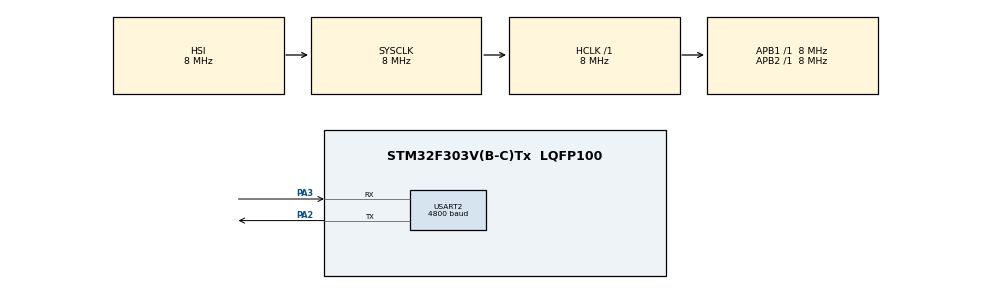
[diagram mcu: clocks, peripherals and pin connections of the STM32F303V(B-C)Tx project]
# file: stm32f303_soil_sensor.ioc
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Mcu.Family=STM32F3
Mcu.Name=STM32F303V(B-C)Tx
Mcu.Package=LQFP100
NVIC.PriorityGroup=NVIC_PRIORITYGROUP_4
NVIC.USART2_IRQn=true\:0\:0\:false\:false\:true\:true\:true\:true
PA13.Mode=Serial_Wire
PA13.Signal=SYS_JTMS-SWDIO
PA14.Mode=Serial_Wire
PA14.Signal=SYS_JTCK-SWCLK
PA2.Mode=Asynchronous
PA2.Signal=USART2_TX
PA3.Mode=Asynchronous
PA3.Signal=USART2_RX
PF0-OSC_IN.Mode=HSE-External-Oscillator
PF0-OSC_IN.Signal=RCC_OSC_IN
PF1-OSC_OUT.Mode=HSE-External-Oscillator
PF1-OSC_OUT.Signal=RCC_OSC_OUT
ProjectManager.HeapSize=0x200
ProjectManager.StackSize=0x400
ProjectManager.TargetToolchain=STM32CubeIDE
RCC.AHBFreq_Value=8000000
RCC.APB1Freq_Value=8000000
RCC.APB2Freq_Value=8000000
RCC.CortexFreq_Value=8000000
RCC.HSE_VALUE=8000000
RCC.HSI_VALUE=8000000
RCC.LSE_VALUE=32768
RCC.SYSCLKFreq_VALUE=8000000
USART2.BaudRate=4800
USART2.VirtualMode-Asynchronous=VM_ASYNC
board=custom

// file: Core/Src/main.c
/* USER CODE BEGIN Header */
/**
  ******************************************************************************
  * @file           : main.c
  * @brief          : Main program body
  ******************************************************************************
  * @attention
  *
  * Copyright (c) 2025 STMicroelectronics.
  * All rights reserved.
  *
  * This software is licensed under terms that can be found in the LICENSE file
  * in the root directory of this software component.
  * If no LICENSE file comes with this software, it is provided AS-IS.
  *
  ******************************************************************************
  */
/* USER CODE END Header */
#include "main.h"

/* USER CODE BEGIN Includes */
#include "modbus_crc.h"
#include "stdint.h"
/* USER CODE END Includes */

UART_HandleTypeDef huart2;

/* USER CODE BEGIN PV */
uint8_t uart2_tx_data[8];
/* USER CODE END PV */

void SystemClock_Config(void);
static void MX_GPIO_Init(void);
static void MX_USART2_UART_Init(void);
/* USER CODE BEGIN PFP */
uint8_t uart2_rx_data[15];
uint16_t recv_data[2];
float moisture = 0.0;
uint16_t moisture_raw = 0;
uint16_t temperature_raw = 0;
uint16_t ec_raw = 0;
/* USER CODE END PFP */

/* USER CODE BEGIN 0 */
void modbus_tx_data() {
    uint8_t uart2_tx_data[8] = {0x01, 0x03, 0x00, 0x00, 0x00, 0x03};
//    // Initialize the global array
//    uart2_tx_data[0] = 0x01; // Slave address
//    uart2_tx_data[1] = 0x03; // Function code
//    uart2_tx_data[2] = 0x00; // Starting address (high byte)
//    uart2_tx_data[3] = 0x00; // Starting address (low byte)
//    uart2_tx_data[4] = 0x00; // Number of registers (high byte)
//    uart2_tx_data[5] = 0x03; // Number of registers (low byte)

    // Calculate CRC for the first 6 bytes
    uint16_t crc = crc16(uart2_tx_data, 6);
    uart2_tx_data[6] = crc & 0xFF;       // CRC LOW
    uart2_tx_data[7] = (crc >> 8) & 0xFF; // CRC HIGH

    // Set DE/RE pin LOW to set MAX485 as transmitter mode
//    HAL_GPIO_WritePin(GPIOA, GPIO_PIN_8, 1); // Transmit mode
    HAL_UART_Transmit(&huart2, uart2_tx_data, 8, 1000); // Send data
    HAL_Delay(10);
    HAL_UART_Receive(&huart2, uart2_rx_data, 15, 1000);
//    HAL_GPIO_WritePin(GPIOA, GPIO_PIN_8, 0); // Set MAX485 back to receiver mode
    // Process the received data
	if (uart2_rx_data[0] == 0x01 && uart2_rx_data[1] == 0x03) { // Valid response
		moisture_raw = (uart2_rx_data[3] << 8) | uart2_rx_data[4];
		temperature_raw = (uart2_rx_data[5] << 8) | uart2_rx_data[6];
		ec_raw = (uart2_rx_data[7] << 8) | uart2_rx_data[8];
//        moisture = moisture_raw / 10.0;       // Convert to %
//        float temperature = temperature_raw / 10.0; // Convert to °C
//        float ec = ec_raw;                          // EC in µS/cm
	}
}

/* USER CODE END 0 */

int main(void)
{

  /* MCU Configuration--------------------------------------------------------*/

  /* Reset of all peripherals, Initializes the Flash interface and the Systick. */
  HAL_Init();

  /* Configure the system clock */
  SystemClock_Config();

  /* Initialize all configured peripherals */
  MX_GPIO_Init();
  MX_USART2_UART_Init();
  /* USER CODE BEGIN 2 */
  // Enable the receive interrupt
//  HAL_UARTEx_ReceiveToIdle_IT(&huart2, uart2_rx_data, 32);
//  HAL_UART_Receive_IT(&huart2, uart2_rx_data, 15);
  /* USER CODE END 2 */

  /* Infinite loop */
  while (1)
  {

    /* USER CODE BEGIN 3 */
	modbus_tx_data();
	HAL_Delay(1000);
  }
  /* USER CODE END 3 */
}

void SystemClock_Config(void)
{
  RCC_OscInitTypeDef RCC_OscInitStruct = {0};
  RCC_ClkInitTypeDef RCC_ClkInitStruct = {0};
  RCC_PeriphCLKInitTypeDef PeriphClkInit = {0};

  /** Initializes the RCC Oscillators according to the specified parameters
  * in the RCC_OscInitTypeDef structure.
  */
  RCC_OscInitStruct.OscillatorType = RCC_OSCILLATORTYPE_HSI;
  RCC_OscInitStruct.HSIState = RCC_HSI_ON;
  RCC_OscInitStruct.HSICalibrationValue = RCC_HSICALIBRATION_DEFAULT;
  RCC_OscInitStruct.PLL.PLLState = RCC_PLL_NONE;
  if (HAL_RCC_OscConfig(&RCC_OscInitStruct) != HAL_OK)
  {
    Error_Handler();
  }

  /** Initializes the CPU, AHB and APB buses clocks
  */
  RCC_ClkInitStruct.ClockType = RCC_CLOCKTYPE_HCLK|RCC_CLOCKTYPE_SYSCLK
                              |RCC_CLOCKTYPE_PCLK1|RCC_CLOCKTYPE_PCLK2;
  RCC_ClkInitStruct.SYSCLKSource = RCC_SYSCLKSOURCE_HSI;
  RCC_ClkInitStruct.AHBCLKDivider = RCC_SYSCLK_DIV1;
  RCC_ClkInitStruct.APB1CLKDivider = RCC_HCLK_DIV1;
  RCC_ClkInitStruct.APB2CLKDivider = RCC_HCLK_DIV1;

  if (HAL_RCC_ClockConfig(&RCC_ClkInitStruct, FLASH_LATENCY_0) != HAL_OK)
  {
    Error_Handler();
  }
  PeriphClkInit.PeriphClockSelection = RCC_PERIPHCLK_USART2;
  PeriphClkInit.Usart2ClockSelection = RCC_USART2CLKSOURCE_PCLK1;
  if (HAL_RCCEx_PeriphCLKConfig(&PeriphClkInit) != HAL_OK)
  {
    Error_Handler();
  }
}

static void MX_USART2_UART_Init(void)
{

  huart2.Instance = USART2;
  huart2.Init.BaudRate = 4800;
  huart2.Init.WordLength = UART_WORDLENGTH_8B;
  huart2.Init.StopBits = UART_STOPBITS_1;
  huart2.Init.Parity = UART_PARITY_NONE;
  huart2.Init.Mode = UART_MODE_TX_RX;
  huart2.Init.HwFlowCtl = UART_HWCONTROL_NONE;
  huart2.Init.OverSampling = UART_OVERSAMPLING_16;
  huart2.Init.OneBitSampling = UART_ONE_BIT_SAMPLE_DISABLE;
  huart2.AdvancedInit.AdvFeatureInit = UART_ADVFEATURE_NO_INIT;
  if (HAL_UART_Init(&huart2) != HAL_OK)
  {
    Error_Handler();
  }

}

static void MX_GPIO_Init(void)
{

  /* GPIO Ports Clock Enable */
  __HAL_RCC_GPIOF_CLK_ENABLE();
  __HAL_RCC_GPIOA_CLK_ENABLE();

}

/* USER CODE BEGIN 4 */
//void HAL_UART_RxCpltCallback(UART_HandleTypeDef *huart)
//{
//    HAL_UART_Transmit(&huart2, uart2_tx_data, 8, 100);
//    HAL_UART_Receive_IT(&huart2, uart2_rx_data, 15);
//}
/* USER CODE END 4 */

void Error_Handler(void)
{
  __disable_irq();
  while (1)
  {
  }
}
